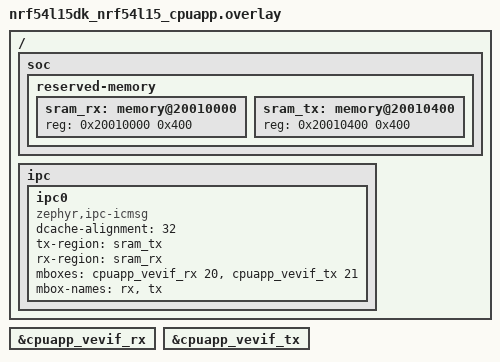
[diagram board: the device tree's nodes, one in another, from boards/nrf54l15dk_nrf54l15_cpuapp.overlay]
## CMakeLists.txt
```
#
# Copyright (c) 2024 Nordic Semiconductor ASA
#
# SPDX-License-Identifier: LicenseRef-Nordic-5-Clause
#

cmake_minimum_required(VERSION 3.20.0)

find_package(Zephyr REQUIRED HINTS $ENV{ZEPHYR_BASE})
project(ipc_service)

target_sources(app PRIVATE src/main.c)
```

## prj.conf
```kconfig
# Copyright (c) 2024 Nordic Semiconductor ASA
# SPDX-License-Identifier: LicenseRef-Nordic-5-Clause

CONFIG_PRINTK=y

CONFIG_LOG=y
CONFIG_LOG_PROCESS_THREAD_PRIORITY=-15
CONFIG_LOG_PROCESS_THREAD_CUSTOM_PRIORITY=y

CONFIG_HEAP_MEM_POOL_SIZE=4096

# BELLBOARD (MBOX) for inter-core interrupts
CONFIG_MBOX=y

# Disable IPC Service - using simple ping-pong buffer instead
# CONFIG_IPC_SERVICE=y
# CONFIG_IPC_SERVICE_LOG_LEVEL_INF=y
```

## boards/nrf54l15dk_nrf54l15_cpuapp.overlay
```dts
/*
 * IPC configuration for XIP memory layout
 * Shared memory region: 160KB (0x20010000-0x20038000)
 */

/ {
	soc {
		reserved-memory {
			#address-cells = <1>;
			#size-cells = <1>;

			// Shared IPC buffers within 160KB shared region
			// RX buffer: 1KB at start of shared memory
			sram_rx: memory@20010000 {
				reg = <0x20010000 0x400>;  // 1KB
			};

			// TX buffer: 1KB immediately after RX
			sram_tx: memory@20010400 {
				reg = <0x20010400 0x400>;  // 1KB
			};

			// Remaining 158KB (0x20010800-0x20038000) available for application buffers
		};
	};

	ipc {
		ipc0: ipc0 {
			compatible = "zephyr,ipc-icmsg";
			dcache-alignment = <32>;
			tx-region = <&sram_tx>;
			rx-region = <&sram_rx>;
			mboxes = <&cpuapp_vevif_rx 20>, <&cpuapp_vevif_tx 21>;
			mbox-names = "rx", "tx";
			status = "okay";
		};
	};
};

&cpuapp_vevif_rx {
	status = "okay";
};

&cpuapp_vevif_tx {
	status = "okay";
};
```

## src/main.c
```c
/*
 * Copyright (c) 2025 Nordic Semiconductor ASA
 *
 * SPDX-License-Identifier: LicenseRef-Nordic-5-Clause
 *
 * Simple BELLBOARD Interrupt Test - M33 Side
 * 
 * This test validates basic BELLBOARD interrupt functionality:
 * - M33 receives interrupts from FLPR
 * - M33 sends interrupts to FLPR
 * - Shared memory communication works
 */

#include <zephyr/kernel.h>
#include <zephyr/device.h>
#include <zephyr/drivers/mbox.h>
#include <zephyr/logging/log.h>
#include <string.h>
#include "ipc_pingpong.h"

LOG_MODULE_REGISTER(m33_bellboard_test, LOG_LEVEL_INF);

/* Control block structure in shared memory */
struct control_block {
	volatile uint32_t flpr_counter;
	volatile uint32_t m33_counter;
	volatile uint32_t flpr_to_m33_count;
	volatile uint32_t m33_to_flpr_count;
};

static struct control_block *ctrl = (struct control_block *)CONTROL_BLOCK_ADDR;

/**
 * Initialize the ping-pong buffer control block
 * 
 * This function:
 * - Zeros the entire control block structure
 * - Sets both buffer states to IDLE
 * - Initializes all counters to zero
 * - Executes a memory barrier to ensure visibility
 * 
 * Requirements: 8.1, 8.2, 8.3
 * 
 * @return BUFFER_OK on success, BUFFER_ERR_INIT on failure
 */
static int control_block_init(void)
{
	control_block_t *cb = CONTROL_BLOCK;
	
	/* Zero entire control block structure */
	memset((void *)cb, 0, sizeof(control_block_t));
	
	/* Set both buffer states to IDLE */
	cb->buffer_states[0] = BUFFER_STATE_IDLE;
	cb->buffer_states[1] = BUFFER_STATE_IDLE;
	
	/* Initialize all counters to zero (already done by memset, but explicit for clarity) */
	cb->write_count[0] = 0;
	cb->write_count[1] = 0;
	cb->read_count[0] = 0;
	cb->read_count[1] = 0;
	cb->overrun_count = 0;
	cb->timeout_count = 0;
	
	/* Initialize timestamps */
	cb->last_write_ts[0] = 0;
	cb->last_write_ts[1] = 0;
	cb->last_read_ts[0] = 0;
	cb->last_read_ts[1] = 0;
	
	/* Initialize synchronization flags */
	cb->flpr_ready = 0;
	cb->m33_ready = 1;  /* M33 is ready after initialization */
	
	/* Set configuration */
	cb->buffer_size = BUFFER_SIZE;
	cb->timeout_ms = 1000;  /* Default 1 second timeout */
	
	/* Execute memory barrier to ensure all writes are visible to FLPR */
	MEMORY_BARRIER_FULL();
	
	return BUFFER_OK;
}

/* MBOX device for BELLBOARD */
static const struct device *mbox_dev;
static const struct device *mbox_tx_dev;

/* Work queue for processing buffers outside of ISR context */
static struct k_work process_buffer_work;
static K_SEM_DEFINE(buffer_ready_sem, 0, 1);

/**
 * Process ready buffer (called from work queue)
 * 
 * This function:
 * - Acquires ready buffer (non-blocking)
 * - Reads and validates data from buffer
 * - Releases buffer and notifies FLPR
 * - Logs statistics periodically
 * 
 * Requirements: 5.1, 5.2, 5.3, 5.4, 5.5
 */
static void process_buffer_handler(struct k_work *work)
{
	ARG_UNUSED(work);
	buffer_handle_t buf;
	int ret;
	
	/* Try to acquire a ready buffer (non-blocking) */
	ret = buffer_acquire_for_read(&buf, 0);
	
	if (ret == BUFFER_ERR_TIMEOUT) {
		/* No buffer ready - this is normal, ISR may have been spurious */
		LOG_DBG("No buffer ready to process");
		return;
	} else if (ret != BUFFER_OK) {
		LOG_ERR("Failed to acquire buffer for reading: %d", ret);
		return;
	}
	
	/* Successfully acquired buffer - validate data */
	uint32_t *data = (uint32_t *)buf.data;
	uint32_t expected_base = data[0];  /* First value is the pattern base */
	bool data_valid = true;
	
	/* Validate test pattern: should be incrementing values */
	for (size_t i = 0; i < (buf.size / sizeof(uint32_t)); i++) {
		if (data[i] != (expected_base + i)) {
			LOG_ERR("Data corruption in buffer %d at offset %zu: expected 0x%08X, got 0x%08X",
			        buf.id, i, expected_base + i, data[i]);
			data_valid = false;
			break;  /* Stop checking after first error */
		}
	}
	
	if (data_valid) {
		LOG_INF("M33: Validated buffer %d (pattern base: 0x%08X)", buf.id, expected_base);
	} else {
		LOG_ERR("M33: Buffer %d validation FAILED", buf.id);
	}
	
	/* Release buffer and notify FLPR */
	ret = buffer_release(&buf);
	
	if (ret != BUFFER_OK) {
		LOG_ERR("Failed to release buffer %d: %d", buf.id, ret);
		/* This is a critical error - buffer may be stuck in READING state */
	} else {
		LOG_DBG("M33: Released buffer %d", buf.id);
	}
}

/**
 * Notify FLPR core via VEVIF interrupt
 * 
 * This function:
 * - Executes a memory barrier to ensure all writes are visible
 * - Triggers a VEVIF interrupt to FLPR (channel 21)
 * - Handles errors from mbox_send
 * 
 * Requirements: 4.4, 7.1
 * 
 * @return BUFFER_OK on success, BUFFER_ERR_INVALID on failure
 */
static int vevif_notify_flpr(void)
{
	int ret;
	
	/* Execute memory barrier before VEVIF trigger to ensure data visibility */
	MEMORY_BARRIER_FULL();
	
	/* Trigger VEVIF interrupt to FLPR */
	ret = mbox_send_dt(&(struct mbox_dt_spec){
		.dev = mbox_tx_dev,
		.channel_id = 21
	}, NULL);
	
	if (ret < 0) {
		LOG_ERR("Failed to notify FLPR: %d", ret);
		return BUFFER_ERR_INVALID;
	}
	
	return BUFFER_OK;
}

/**
 * Acquire next ready buffer for reading (M33 read path)
 * 
 * This function:
 * - Searches for next READY buffer in FIFO order (uses timestamps)
 * - Uses atomic CAS to transition READY → READING
 * - Implements timeout using k_uptime_get() and polling
 * - Returns buffer handle with pointer to data region
 * 
 * Requirements: 5.1, 5.2, 5.5
 * 
 * @param handle Pointer to buffer_handle_t to populate
 * @param timeout_ms Timeout in milliseconds (0 = non-blocking)
 * @return BUFFER_OK on success, BUFFER_ERR_TIMEOUT on timeout, BUFFER_ERR_INVALID on invalid params
 */
int buffer_acquire_for_read(buffer_handle_t *handle, uint32_t timeout_ms)
{
	uint64_t start_time;
	uint64_t current_time;
	
	/* Validate parameters */
	if (handle == NULL) {
		LOG_ERR("Invalid handle parameter");
		return BUFFER_ERR_INVALID;
	}
	
	/* Record start time for timeout */
	start_time = k_uptime_get();
	
	/* Try to acquire a READY buffer with timeout */
	while (1) {
		/* Find the oldest READY buffer (FIFO order using timestamps) */
		int8_t oldest_buffer = -1;
		uint64_t oldest_timestamp = UINT64_MAX;
		
		/* Check both buffers for READY state */
		for (uint8_t i = 0; i < 2; i++) {
			buffer_state_t state = buffer_get_state(i);
			
			if (state == BUFFER_STATE_READY) {
				/* Get timestamp for this buffer */
				uint64_t timestamp = CONTROL_BLOCK->last_write_ts[i];
				
				/* Track the oldest (earliest timestamp) READY buffer */
				if (timestamp < oldest_timestamp) {
					oldest_timestamp = timestamp;
					oldest_buffer = i;
				}
			}
		}
		
		/* If we found a READY buffer, try to acquire it */
		if (oldest_buffer >= 0) {
			/* Try to atomically transition READY → READING */
			if (atomic_cas_state(&CONTROL_BLOCK->buffer_states[oldest_buffer],
			                     BUFFER_STATE_READY,
			                     BUFFER_STATE_READING)) {
				/* Successfully acquired buffer */
				handle->id = oldest_buffer;
				handle->data = (void *)(oldest_buffer == 0 ? BUFFER_0_ADDR : BUFFER_1_ADDR);
				handle->size = BUFFER_SIZE;
				handle->state = &CONTROL_BLOCK->buffer_states[oldest_buffer];
				
				LOG_DBG("Acquired buffer %d for reading (timestamp: %llu)", 
				        oldest_buffer, oldest_timestamp);
				return BUFFER_OK;
			}
			/* CAS failed, another core may have acquired it, continue trying */
		}
		
		/* Check timeout */
		current_time = k_uptime_get();
		if ((current_time - start_time) >= timeout_ms) {
			LOG_WRN("Buffer read acquisition timeout after %u ms", timeout_ms);
			atomic_inc((atomic_t *)&CONTROL_BLOCK->timeout_count);
			return BUFFER_ERR_TIMEOUT;
		}
		
		/* Small delay before retry to avoid busy-waiting */
		k_usleep(100);
	}
	
	/* Should never reach here */
	return BUFFER_ERR_INVALID;
}

/**
 * Release processed buffer and notify FLPR (M33 read path)
 * 
 * This function:
 * - Uses atomic CAS to transition READING → IDLE
 * - Executes memory barrier before notification
 * - Calls vevif_notify_flpr() to trigger interrupt
 * - Increments read counter for the buffer
 * - Records timestamp using k_uptime_get()
 * 
 * Requirements: 5.4, 4.2, 7.2, 10.1, 10.2
 * 
 * @param handle Pointer to buffer_handle_t to release
 * @return BUFFER_OK on success, BUFFER_ERR_INVALID on invalid params, BUFFER_ERR_STATE on wrong state
 */
int buffer_release(buffer_handle_t *handle)
{
	int ret;
	
	/* Validate parameters */
	if (handle == NULL) {
		LOG_ERR("Invalid handle parameter");
		return BUFFER_ERR_INVALID;
	}
	
	if (handle->id > 1) {
		LOG_ERR("Invalid buffer ID: %d", handle->id);
		return BUFFER_ERR_INVALID;
	}
	
	/* Try to atomically transition READING → IDLE */
	if (!atomic_cas_state(&CONTROL_BLOCK->buffer_states[handle->id],
	                      BUFFER_STATE_READING,
	                      BUFFER_STATE_IDLE)) {
		/* CAS failed - buffer is not in READING state */
		buffer_state_t current_state = buffer_get_state(handle->id);
		LOG_ERR("Failed to release buffer %d: wrong state (expected READING, got %d)",
		        handle->id, current_state);
		return BUFFER_ERR_STATE;
	}
	
	/* Increment read counter for this buffer */
	atomic_inc((atomic_t *)&CONTROL_BLOCK->read_count[handle->id]);
	
	/* Record timestamp */
	uint64_t timestamp = k_uptime_get();
	CONTROL_BLOCK->last_read_ts[handle->id] = timestamp;
	
	/* Execute memory barrier before notification to ensure data visibility */
	MEMORY_BARRIER_FULL();
	
	/* Notify FLPR that buffer is now IDLE */
	ret = vevif_notify_flpr();
	if (ret != BUFFER_OK) {
		LOG_ERR("Failed to notify FLPR after buffer release: %d", ret);
		/* Note: Buffer state is already IDLE, so this is not a critical error */
		return ret;
	}
	
	LOG_DBG("Released buffer %d (read count: %u, timestamp: %llu)",
	        handle->id, CONTROL_BLOCK->read_count[handle->id], timestamp);
	
	return BUFFER_OK;
}

/* Callback for BELLBOARD interrupt from FLPR */
static void mbox_callback(const struct device *dev, uint32_t channel,
			  void *user_data, struct mbox_msg *msg)
{
	ARG_UNUSED(dev);
	ARG_UNUSED(user_data);
	ARG_UNUSED(msg);

	/* Increment interrupt counter for legacy compatibility */
	ctrl->flpr_to_m33_count++;

	LOG_DBG("M33: Received interrupt #%d from FLPR", ctrl->flpr_to_m33_count);
	
	/* Schedule work queue to process buffer outside ISR context */
	k_work_submit(&process_buffer_work);
}

int main(void)
{
	int ret;

	LOG_INF("=== M33 VEVIF Interrupt Test ===");
	LOG_INF("Shared memory base: 0x%08X", (uint32_t)SHARED_MEM_BASE);
	LOG_INF("Control block: 0x%08X", (uint32_t)CONTROL_BLOCK_ADDR);

	/* Initialize ping-pong buffer control block */
	ret = control_block_init();
	if (ret != BUFFER_OK) {
		LOG_ERR("Failed to initialize control block: %d", ret);
		return ret;
	}

	LOG_INF("Ping-pong buffer control block initialized");

	/* Initialize work queue for buffer processing */
	k_work_init(&process_buffer_work, process_buffer_handler);
	LOG_INF("Work queue initialized");

	/* Initialize old control block for backward compatibility */
	ctrl->flpr_counter = 0;
	ctrl->m33_counter = 0;
	ctrl->flpr_to_m33_count = 0;
	ctrl->m33_to_flpr_count = 0;

	LOG_INF("Legacy control block initialized");

	/* Get MBOX device (VEVIF RX) */
	mbox_dev = DEVICE_DT_GET(DT_NODELABEL(cpuapp_vevif_rx));
	if (!device_is_ready(mbox_dev)) {
		LOG_ERR("MBOX RX device not ready");
		return -ENODEV;
	}

	LOG_INF("MBOX RX device ready");

	/* Configure RX channel (receive from FLPR) - Channel 20 */
	ret = mbox_set_enabled_dt(&(struct mbox_dt_spec){
		.dev = mbox_dev,
		.channel_id = 20
	}, true);
	if (ret < 0) {
		LOG_ERR("Failed to enable RX channel: %d", ret);
		return ret;
	}

	/* Register callback for interrupts from FLPR */
	ret = mbox_register_callback_dt(&(struct mbox_dt_spec){
		.dev = mbox_dev,
		.channel_id = 20
	}, mbox_callback, NULL);
	if (ret < 0) {
		LOG_ERR("Failed to register callback: %d", ret);
		return ret;
	}

	LOG_INF("RX channel configured (Channel 20: FLPR -> M33)");

	/* Get TX device */
	mbox_tx_dev = DEVICE_DT_GET(DT_NODELABEL(cpuapp_vevif_tx));
	if (!device_is_ready(mbox_tx_dev)) {
		LOG_ERR("MBOX TX device not ready");
		return -ENODEV;
	}

	LOG_INF("TX channel configured (Channel 21: M33 -> FLPR)");
	LOG_INF("Waiting for FLPR to start...");

	/* Wait a bit for FLPR to initialize */
	k_msleep(500);

	LOG_INF("Starting ping-pong buffer processing...");

	/* Main loop: log statistics periodically */
	while (1) {
		/* Log statistics every 5 seconds */
		LOG_INF("=== M33 Statistics ===");
		LOG_INF("  Buffer 0 reads: %u", CONTROL_BLOCK->read_count[0]);
		LOG_INF("  Buffer 1 reads: %u", CONTROL_BLOCK->read_count[1]);
		LOG_INF("  Interrupts received: %u", ctrl->flpr_to_m33_count);
		LOG_INF("  Overruns: %u", CONTROL_BLOCK->overrun_count);
		LOG_INF("  Timeouts: %u", CONTROL_BLOCK->timeout_count);
		
		/* Calculate and log buffer utilization */
		uint32_t total_writes = CONTROL_BLOCK->write_count[0] + CONTROL_BLOCK->write_count[1];
		uint32_t total_reads = CONTROL_BLOCK->read_count[0] + CONTROL_BLOCK->read_count[1];
		
		if (total_writes > 0) {
			uint32_t utilization = (total_reads * 100) / total_writes;
			LOG_INF("  Buffer utilization: %u%% (%u reads / %u writes)",
			        utilization, total_reads, total_writes);
		}
		
		k_msleep(5000);
	}

	return 0;
}
```

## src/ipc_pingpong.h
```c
/*
 * Copyright (c) 2025 Nordic Semiconductor ASA
 *
 * SPDX-License-Identifier: Apache-2.0
 */

#ifndef IPC_PINGPONG_H
#define IPC_PINGPONG_H

#include <stdint.h>
#include <stddef.h>
#include <stdbool.h>
#include <zephyr/sys/atomic.h>

#ifdef __cplusplus
extern "C" {
#endif

/* Memory Layout Constants */
#define SHARED_MEM_BASE     0x20010000UL
#define BUFFER_SIZE         (64 * 1024)
#define CONTROL_BLOCK_SIZE  (32 * 1024)

/* Buffer addresses */
#define BUFFER_0_ADDR       (SHARED_MEM_BASE)
#define BUFFER_1_ADDR       (SHARED_MEM_BASE + BUFFER_SIZE)
#define CONTROL_BLOCK_ADDR  (SHARED_MEM_BASE + 2 * BUFFER_SIZE)

/* Buffer States */
typedef enum {
    BUFFER_STATE_IDLE = 0,
    BUFFER_STATE_WRITING,
    BUFFER_STATE_READY,
    BUFFER_STATE_READING
} buffer_state_t;

/* Ensure buffer_state_t is 32-bit for atomic operations */
_Static_assert(sizeof(buffer_state_t) <= sizeof(atomic_val_t), 
               "buffer_state_t must fit in atomic_val_t");

/* Error Codes */
#define BUFFER_OK              0
#define BUFFER_ERR_TIMEOUT    -1
#define BUFFER_ERR_INVALID    -2
#define BUFFER_ERR_STATE      -3
#define BUFFER_ERR_OVERRUN    -4
#define BUFFER_ERR_INIT       -5

/* Memory Barrier Macros */
#if defined(__ARM_ARCH)
    /* ARM Cortex-M33 memory barriers */
    #define MEMORY_BARRIER_WRITE() __asm__ volatile("dmb st" ::: "memory")
    #define MEMORY_BARRIER_READ()  __asm__ volatile("dmb ld" ::: "memory")
    #define MEMORY_BARRIER_FULL()  __asm__ volatile("dmb sy" ::: "memory")
#elif defined(__riscv)
    /* RISC-V memory barriers */
    #define MEMORY_BARRIER_WRITE() __asm__ volatile("fence ow, ow" ::: "memory")
    #define MEMORY_BARRIER_READ()  __asm__ volatile("fence ir, ir" ::: "memory")
    #define MEMORY_BARRIER_FULL()  __asm__ volatile("fence iorw, iorw" ::: "memory")
#else
    /* Generic compiler barriers as fallback */
    #define MEMORY_BARRIER_WRITE() __asm__ volatile("" ::: "memory")
    #define MEMORY_BARRIER_READ()  __asm__ volatile("" ::: "memory")
    #define MEMORY_BARRIER_FULL()  __asm__ volatile("" ::: "memory")
#endif

/* Control Block Structure */
typedef struct {
    /* Buffer states (use uint32_t for atomic operations, aligned to 64 bytes) */
    volatile uint32_t buffer_states[2] __attribute__((aligned(64)));
    
    /* Transfer counters (aligned to 4 bytes) */
    volatile uint32_t write_count[2] __attribute__((aligned(4)));
    volatile uint32_t read_count[2] __attribute__((aligned(4)));
    
    /* Error counters (aligned to 4 bytes) */
    volatile uint32_t overrun_count __attribute__((aligned(4)));
    volatile uint32_t timeout_count __attribute__((aligned(4)));
    
    /* Timestamps (for debugging, aligned to 8 bytes) */
    volatile uint64_t last_write_ts[2] __attribute__((aligned(8)));
    volatile uint64_t last_read_ts[2] __attribute__((aligned(8)));
    
    /* Synchronization flags (aligned to 4 bytes) */
    volatile uint32_t flpr_ready __attribute__((aligned(4)));
    volatile uint32_t m33_ready __attribute__((aligned(4)));
    
    /* Configuration (aligned to 4 bytes) */
    uint32_t buffer_size __attribute__((aligned(4)));
    uint32_t timeout_ms __attribute__((aligned(4)));
    
    /* Reserved for future use */
    uint8_t reserved[31744];
} control_block_t;

/* Global control block pointer */
#define CONTROL_BLOCK ((control_block_t *)CONTROL_BLOCK_ADDR)

/* Buffer Handle Structure */
typedef struct {
    uint8_t id;                          /* Buffer ID (0 or 1) */
    void *data;                          /* Pointer to buffer data */
    size_t size;                         /* Buffer size (64KB) */
    volatile uint32_t *state;            /* Pointer to state in control block */
} buffer_handle_t;

/* Statistics Structure */
typedef struct {
    /* Per-buffer statistics */
    uint32_t writes[2];
    uint32_t reads[2];
    uint64_t last_write_ts[2];
    uint64_t last_read_ts[2];
    
    /* Error statistics */
    uint32_t overruns;
    uint32_t timeouts;
    uint32_t state_errors;
    
    /* Performance metrics */
    uint32_t avg_write_latency_us;
    uint32_t avg_read_latency_us;
    uint32_t max_latency_us;
} buffer_stats_t;

/* Atomic State Transition Functions */
static inline bool atomic_cas_state(
    volatile uint32_t *state,
    buffer_state_t expected,
    buffer_state_t desired)
{
    /* Use Zephyr's atomic API for portability across architectures */
    atomic_val_t exp_val = (atomic_val_t)expected;
    return atomic_cas((atomic_t *)state, exp_val, (atomic_val_t)desired);
}

/* Query buffer state (non-blocking) */
static inline buffer_state_t buffer_get_state(uint8_t buffer_id)
{
    if (buffer_id > 1) {
        return BUFFER_STATE_IDLE;  /* Invalid buffer ID */
    }
    /* Use Zephyr's atomic API for safe read */
    atomic_val_t state = atomic_get((atomic_t *)&CONTROL_BLOCK->buffer_states[buffer_id]);
    return (buffer_state_t)state;
}

/* Function Prototypes */

/* Initialize the buffer manager */
int buffer_manager_init(void);

/* FLPR: Acquire next available buffer for writing */
int buffer_acquire_for_write(buffer_handle_t *handle, uint32_t timeout_ms);

/* FLPR: Commit written buffer and notify M33 */
int buffer_commit(buffer_handle_t *handle);

/* M33: Acquire next ready buffer for reading */
int buffer_acquire_for_read(buffer_handle_t *handle, uint32_t timeout_ms);

/* M33: Release processed buffer and notify FLPR */
int buffer_release(buffer_handle_t *handle);

/* Get statistics */
void buffer_get_stats(buffer_stats_t *stats);

#ifdef __cplusplus
}
#endif

#endif /* IPC_PINGPONG_H */
```
